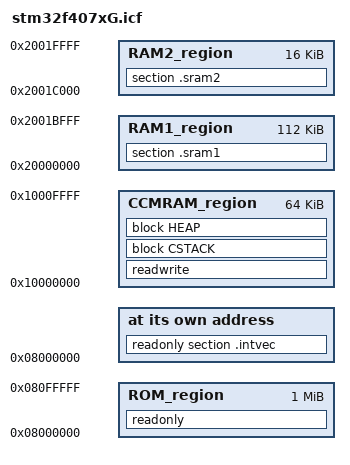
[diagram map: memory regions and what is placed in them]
/*###ICF### Section handled by ICF editor, don't touch! ****/
/*-Editor annotation file-*/
/* IcfEditorFile="$TOOLKIT_DIR$\config\ide\IcfEditor\cortex_v1_0.xml" */
/*-Specials-*/
define symbol __ICFEDIT_intvec_start__ = 0x08000000;
/*-Memory Regions-*/
define symbol __ICFEDIT_region_ROM_start__    = 0x08000000;
define symbol __ICFEDIT_region_ROM_end__      = 0x080FFFFF;
define symbol __ICFEDIT_region_CCMRAM_start__ = 0x10000000;
define symbol __ICFEDIT_region_CCMRAM_end__   = 0x1000FFFF;
define symbol __ICFEDIT_region_RAM1_start__   = 0x20000000;
define symbol __ICFEDIT_region_RAM1_end__     = 0x2001BFFF;
define symbol __ICFEDIT_region_RAM2_start__   = 0x2001C000;
define symbol __ICFEDIT_region_RAM2_end__     = 0x2001FFFF;

/*-Sizes-*/
define symbol __ICFEDIT_size_cstack__ = 0x2000;
/* heap is not used at present (rev 00.29 code), reduced size from x800.  kept at x200 in case it is */
/*   needed in the future                                                                             */
define symbol __ICFEDIT_size_heap__   = 0x0200;
/**** End of ICF editor section. ###ICF###*/

define memory mem with size = 4G;
define region ROM_region    = mem:[from __ICFEDIT_region_ROM_start__     to __ICFEDIT_region_ROM_end__];
define region CCMRAM_region = mem:[from __ICFEDIT_region_CCMRAM_start__  to __ICFEDIT_region_CCMRAM_end__];
define region RAM1_region   = mem:[from __ICFEDIT_region_RAM1_start__    to __ICFEDIT_region_RAM1_end__];
define region RAM2_region   = mem:[from __ICFEDIT_region_RAM2_start__    to __ICFEDIT_region_RAM2_end__];

define block CSTACK    with alignment = 8, size = __ICFEDIT_size_cstack__   { };
define block HEAP      with alignment = 8, size = __ICFEDIT_size_heap__     { };

place at address mem:__ICFEDIT_intvec_start__ { readonly section .intvec };

place in ROM_region     { readonly };
place in CCMRAM_region  { readwrite,
                           block CSTACK, block HEAP };
place in RAM1_region    { section .sram1 };
place in RAM2_region    { section .sram2 };

/* initialize by copy { readwrite };   DAH this line is replaced with the following line to eliminate variable initialization on startup  */
do not initialize  { readwrite };
do not initialize  { section .noinit };
do not initialize  { section .sram1 };
do not initialize  { section .sram2 };

initialize by copy with packing = none { section __DLIB_PERTHREAD };    /* DAH Needed to add to fix problem with using square root library */
                                                                        /*     function.  It is used to initialize error codes (I think)   */
